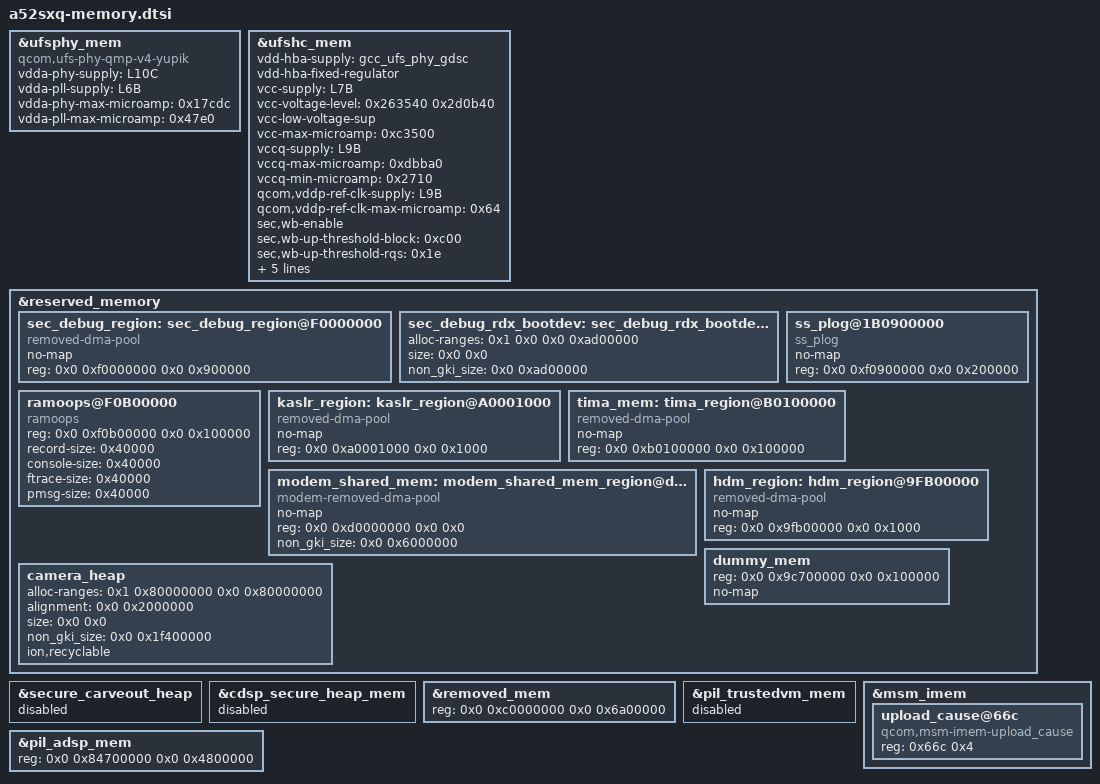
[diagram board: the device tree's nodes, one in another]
// SPDX-License-Identifier: GPL-2.0
/*
 * a52sxq board description for the Qualcomm 6.12 yupik base: memory
 * GENERATED by tools/gen.py from the phone's stock dtbo (5.4 bindings, values verbatim).
 * Do not edit: hand-written 6.12 changes live in a52sxq-bsp612-fixups.dtsi.
 */

&ufsphy_mem {
	compatible = "qcom,ufs-phy-qmp-v4-yupik";
	vdda-phy-supply = <&L10C>;
	vdda-pll-supply = <&L6B>;
	vdda-phy-max-microamp = <0x17cdc>;
	vdda-pll-max-microamp = <0x47e0>;
	status = "ok";
};

&ufshc_mem {
	vdd-hba-supply = <&gcc_ufs_phy_gdsc>;
	vdd-hba-fixed-regulator;
	vcc-supply = <&L7B>;
	vcc-voltage-level = <0x263540 0x2d0b40>;
	vcc-low-voltage-sup;
	vcc-max-microamp = <0xc3500>;
	vccq-supply = <&L9B>;
	vccq-max-microamp = <0xdbba0>;
	vccq-min-microamp = <0x2710>;
	qcom,vddp-ref-clk-supply = <&L9B>;
	qcom,vddp-ref-clk-max-microamp = <0x64>;
	status = "ok";
	sec,wb-enable;
	sec,wb-up-threshold-block = <0xc00>;
	sec,wb-up-threshold-rqs = <0x1e>;
	sec,wb-down-threshold-block = <0x600>;
	sec,wb-down-threshold-rqs = <0x19>;
	sec,wb-disable-threshold-lt = <0x9>;
	sec,wb-on-delay-ms = <0x5c>;
	sec,wb-off-delay-ms = <0x1194>;
};

&reserved_memory {

	sec_debug_region: sec_debug_region@F0000000 {
		compatible = "removed-dma-pool";
		no-map;
		reg = <0x0 0xf0000000 0x0 0x900000>;
	};

	sec_debug_rdx_bootdev: sec_debug_rdx_bootdev@0 {
		alloc-ranges = <0x1 0x0 0x0 0xad00000>;
		size = <0x0 0x0>;
		non_gki_size = <0x0 0xad00000>;
	};

	ss_plog@1B0900000 {
		compatible = "ss_plog";
		no-map;
		reg = <0x0 0xf0900000 0x0 0x200000>;
	};

	ramoops@F0B00000 {
		compatible = "ramoops";
		reg = <0x0 0xf0b00000 0x0 0x100000>;
		record-size = <0x40000>;
		console-size = <0x40000>;
		ftrace-size = <0x40000>;
		pmsg-size = <0x40000>;
	};

	kaslr_region: kaslr_region@A0001000 {
		compatible = "removed-dma-pool";
		no-map;
		reg = <0x0 0xa0001000 0x0 0x1000>;
	};

	tima_mem: tima_region@B0100000 {
		compatible = "removed-dma-pool";
		no-map;
		reg = <0x0 0xb0100000 0x0 0x100000>;
	};

	modem_shared_mem: modem_shared_mem_region@d0000000 {
		compatible = "modem-removed-dma-pool";
		no-map;
		reg = <0x0 0xd0000000 0x0 0x0>;
		non_gki_size = <0x0 0x6000000>;
	};

	hdm_region: hdm_region@9FB00000 {
		compatible = "removed-dma-pool";
		no-map;
		reg = <0x0 0x9fb00000 0x0 0x1000>;
	};

	dummy_mem: dummy_mem {
		reg = <0x0 0x9c700000 0x0 0x100000>;
		no-map;
	};

	camera_heap: camera_heap {
		alloc-ranges = <0x1 0x80000000 0x0 0x80000000>;
		alignment = <0x0 0x2000000>;
		size = <0x0 0x0>;
		non_gki_size = <0x0 0x1f400000>;
		ion,recyclable;
	};
};

&secure_carveout_heap {	/* TODO-binding: label not in the 6.12 base, placeholder */
	status = "disabled";
};

&cdsp_secure_heap_mem {
	status = "disabled";
};

&removed_mem {
	reg = <0x0 0xc0000000 0x0 0x6a00000>;
};

&pil_trustedvm_mem {
	status = "disabled";
};

&pil_adsp_mem {
	reg = <0x0 0x84700000 0x0 0x4800000>;
};

&msm_imem {	/* TODO-binding: label not in the 6.12 base, placeholder */

	upload_cause@66c {
		compatible = "qcom,msm-imem-upload_cause";
		reg = <0x66c 0x4>;
	};
};

